# EFR32FG23B010F512IM48 register map
Vendor: Silicon Labs; Series: EFR32; File version: C
CPU: CM33 r0p4, little endian, MPU, FPU, DSP, VTOR, 4 interrupt priority bits, 8 SAU regions
Registers are 32-bit, read-write, reset 0x0 unless marked. A register's access mark holds for its fields unless they carry their own. Offsets are from the block's base; [hi:lo] are bit positions; 'fields as' and 'values as' point back to an identical list.

## I2C0_NS — I2C0_NS Registers
Base 0x5B000000
Same registers: I2C1_S 0x40068000, I2C0_S 0x4B000000, I2C1_NS 0x50068000
0x00 IPVERSION ro
  [31:0] IPVERSION — IP version ID
0x04 EN
  [0] EN — module enable
    0=DISABLE (Disable Peripheral Clock); 1=ENABLE (Enable Peripheral Clock)
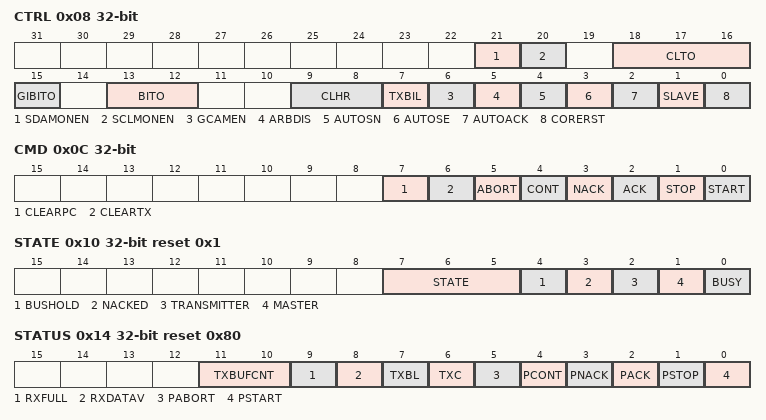
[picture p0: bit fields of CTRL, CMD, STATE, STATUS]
0x08 CTRL
  [21] SDAMONEN — SDA Monitor Enable
    0=DISABLE (Disable SDA Monitor); 1=ENABLE (Enable SDA Monitor)
  [20] SCLMONEN — SCL Monitor Enable
    0=DISABLE (Disable SCL monitor); 1=ENABLE (Enable SCL monitor)
  [18:16] CLTO — Clock Low Timeout
    0=OFF (Timeout disabled); 1=I2C40PCC (Timeout after 40 prescaled clock cycles. In standard mode at 100 kHz, this results in a 50us timeout.); 2=I2C80PCC (Timeout after 80 prescaled clock cycles. In standard mode at 100 kHz, this results in a 100us timeout.); 3=I2C160PCC (Timeout after 160 prescaled clock cycles. In standard mode at 100 kHz, this results in a 200us timeout.); 4=I2C320PCC (Timeout after 320 prescaled clock cycles. In standard mode at 100 kHz, this results in a 400us timeout.); 5=I2C1024PCC (Timeout after 1024 prescaled clock cycles. In standard mode at 100 kHz, this results in a 1280us timeout.)
  [15] GIBITO — Go Idle on Bus Idle Timeout
    0=DISABLE (A bus idle timeout has no effect on the bus state.); 1=ENABLE (A bus idle timeout tells the I2C module that the bus is idle, allowing new transfers to be initiated.)
  [13:12] BITO — Bus Idle Timeout
    0=OFF (Timeout disabled); 1=I2C40PCC (Timeout after 40 prescaled clock cycles. In standard mode at 100 kHz, this results in a 50us timeout.); 2=I2C80PCC (Timeout after 80 prescaled clock cycles. In standard mode at 100 kHz, this results in a 100us timeout.); 3=I2C160PCC (Timeout after 160 prescaled clock cycles. In standard mode at 100 kHz, this results in a 200us timeout.)
  [9:8] CLHR — Clock Low High Ratio
    0=STANDARD (Nlow=4 and Nhigh=4, and the Nlow:Nhigh ratio is 4:4); 1=ASYMMETRIC (Nlow=6 and Nhigh=3, and the Nlow:Nhigh ratio is 6:3); 2=FAST (Nlow=11 and Nhigh=6, and the Nlow:Nhigh ratio is 11:6)
  [7] TXBIL — TX Buffer Interrupt Level
    0=EMPTY (TXBL status and the TXBL interrupt flag are set when the transmit buffer becomes empty. TXBL is cleared when the buffer becomes nonempty.); 1=HALF_FULL (TXBL status and the TXBL interrupt flag are set when the transmit buffer goes from full to half-full or empty. TXBL is cleared when the buffer becomes full)
  [6] GCAMEN — General Call Address Match Enable
    0=DISABLE (General call address will be NACK'ed if it is not included by the follower address and address mask.); 1=ENABLE (When a general call address is received, a software response is required)
  [5] ARBDIS — Arbitration Disable
    0=DISABLE (When a device loses arbitration, the ARBIF interrupt flag is set and the bus is released.); 1=ENABLE (When a device loses arbitration, the ARBIF interrupt flag is set, but communication proceeds.)
  [4] AUTOSN — Automatic STOP on NACK
    0=DISABLE (Stop is not automatically sent if a NACK is received from a follower.); 1=ENABLE (The leader automatically sends a STOP if a NACK is received from a follower.)
  [3] AUTOSE — Automatic STOP when Empty
    0=DISABLE (A stop must be sent manually when no more data is to be transmitted.); 1=ENABLE (The leader automatically sends a STOP when no more data is available for transmission.)
  [2] AUTOACK — Automatic Acknowledge
    0=DISABLE (Software must give one ACK command for each ACK transmitted on the I2C bus.); 1=ENABLE (Addresses that are not automatically NACK'ed, and all data is automatically acknowledged.)
  [1] SLAVE — Addressable as Follower
    0=DISABLE (All addresses will be responded to with a NACK); 1=ENABLE (Addresses matching the programmed follower address or the general call address (if enabled) require a response from software. Other addresses are automatically responded to with a NACK.)
  [0] CORERST — Soft Reset the internal state registers
    0=DISABLE (No change to internal state registers); 1=ENABLE (Reset the internal state registers)
0x0C CMD wo
  [7] CLEARPC — Clear Pending Commands
  [6] CLEARTX
  [5] ABORT — Abort transmission
  [4] CONT — Continue transmission
  [3] NACK — Send NACK
  [2] ACK — Send ACK
  [1] STOP — Send stop condition
  [0] START — Send start condition
0x10 STATE ro reset 0x1
  [7:5] STATE — Transmission State
    0=IDLE (No transmission is being performed.); 1=WAIT (Waiting for idle. Will send a start condition as soon as the bus is idle.); 2=START (Start transmit phase); 3=ADDR (Address transmit or receive phase); 4=ADDRACK (Address ack/nack transmit or receive phase); 5=DATA (Data transmit or receive phase); 6=DATAACK (Data ack/nack transmit or receive phase)
  [4] BUSHOLD — Bus Held
  [3] NACKED — Nack Received
  [2] TRANSMITTER
  [1] MASTER — Leader
  [0] BUSY — Bus Busy
0x14 STATUS ro reset 0x80
  [11:10] TXBUFCNT — TX Buffer Count
  [9] RXFULL — RX FIFO Full
  [8] RXDATAV — RX Data Valid
  [7] TXBL — TX Buffer Level
  [6] TXC — TX Complete
  [5] PABORT — Pending abort
  [4] PCONT — Pending continue
  [3] PNACK — Pending NACK
  [2] PACK — Pending ACK
  [1] PSTOP — Pending STOP
  [0] PSTART — Pending START
0x18 CLKDIV
  [8:0] DIV — Clock Divider
0x1C SADDR
  [7:1] ADDR — Follower address
0x20 SADDRMASK
  [7:1] SADDRMASK — Follower Address Mask
0x24 RXDATA ro
  [7:0] RXDATA
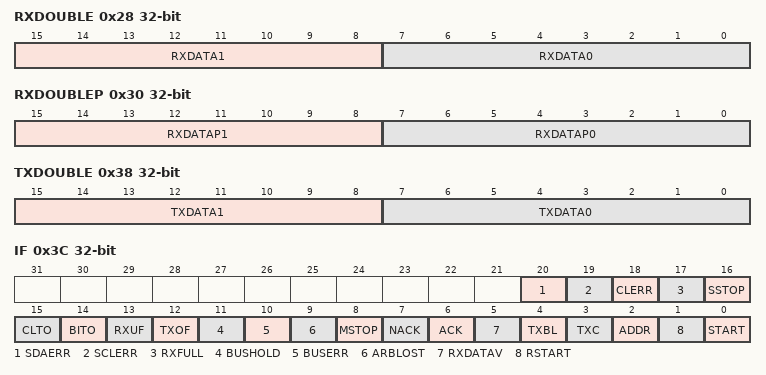
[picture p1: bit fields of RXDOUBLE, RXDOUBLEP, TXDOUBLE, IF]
0x28 RXDOUBLE ro
  [15:8] RXDATA1, [7:0] RXDATA0
0x2C RXDATAP ro
  [7:0] RXDATAP — RX Data Peek
0x30 RXDOUBLEP ro
  [15:8] RXDATAP1 — RX Data 1 Peek
  [7:0] RXDATAP0 — RX Data 0 Peek
0x34 TXDATA wo
  [7:0] TXDATA
0x38 TXDOUBLE wo
  [15:8] TXDATA1 — TX Data
  [7:0] TXDATA0 — TX Data
0x3C IF
  [20] SDAERR — SDA Error Interrupt Flag
  [19] SCLERR — SCL Error Interrupt Flag
  [18] CLERR — Clock Low Error Interrupt Flag
  [17] RXFULL — Receive Buffer Full Interrupt Flag
  [16] SSTOP — Follower STOP condition Interrupt Flag
  [15] CLTO — Clock Low Timeout Interrupt Flag
  [14] BITO — Bus Idle Timeout Interrupt Flag
  [13] RXUF — Receive Buffer Underflow Interrupt Flag
  [12] TXOF — Transmit Buffer Overflow Interrupt Flag
  [11] BUSHOLD — Bus Held Interrupt Flag
  [10] BUSERR — Bus Error Interrupt Flag
  [9] ARBLOST — Arbitration Lost Interrupt Flag
  [8] MSTOP — Leader STOP Condition Interrupt Flag
  [7] NACK — Not Acknowledge Received Interrupt Flag
  [6] ACK — Acknowledge Received Interrupt Flag
  [5] RXDATAV — Receive Data Valid Interrupt Flag
  [4] TXBL — Transmit Buffer Level Interrupt Flag
  [3] TXC — Transfer Completed Interrupt Flag
  [2] ADDR — Address Interrupt Flag
  [1] RSTART — Repeated START condition Interrupt Flag
  [0] START — START condition Interrupt Flag
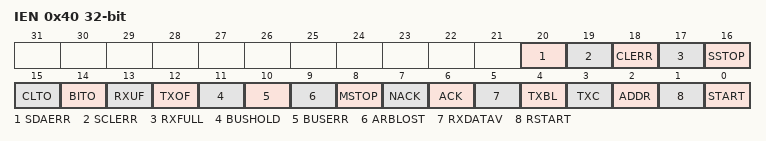
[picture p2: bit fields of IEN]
0x40 IEN
  fields as IF
